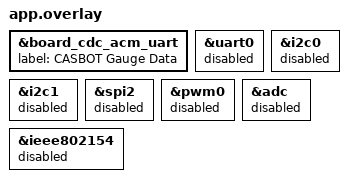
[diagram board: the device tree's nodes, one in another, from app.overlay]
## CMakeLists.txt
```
cmake_minimum_required(VERSION 3.20.0)

find_package(Zephyr REQUIRED HINTS $ENV{ZEPHYR_BASE})
project(trical_bridge LANGUAGES C)

add_subdirectory(lib)
target_sources(app PRIVATE src/main.c)
```

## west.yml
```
manifest:
  version: "1.2"
  self:
    path: trical_bridge
  projects:
    - name: zephyr
      url: https://github.com/zephyrproject-rtos/zephyr
      revision: v4.5.0
      import:
        name-allowlist:
          - cmsis
          - cmsis_6
          - hal_nordic
          - segger
```

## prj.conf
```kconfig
# BLE central/client foundation for three independent indicators. Explicit connections only.
CONFIG_BT=y
CONFIG_BT_CENTRAL=y
CONFIG_BT_GATT_CLIENT=y
CONFIG_BT_MAX_CONN=3
CONFIG_BT_DEVICE_NAME="CASBOT Gauge Bridge"

# Dedicated USB data port; never route the console or logging into it.
CONFIG_USB_DEVICE_STACK_NEXT=y
CONFIG_CDC_ACM_SERIAL_INITIALIZE_AT_BOOT=y
CONFIG_CDC_ACM_SERIAL_PRODUCT_STRING="CASBOT Gauge Bridge (development)"
CONFIG_SERIAL=y
CONFIG_UART_INTERRUPT_DRIVEN=y
CONFIG_UART_LINE_CTRL=y
CONFIG_CONSOLE=n
CONFIG_UART_CONSOLE=n
CONFIG_BOOT_BANNER=n
CONFIG_PRINTK=n

# Diagnostics use a non-blocking RTT backend, independent of USB consumption.
CONFIG_LOG=y
CONFIG_USE_SEGGER_RTT=y
CONFIG_LOG_BACKEND_RTT=y
CONFIG_LOG_BACKEND_UART=n
CONFIG_LOG_BACKEND_RTT_MODE_DROP=y
CONFIG_LOG_PROCESS_THREAD_STARTUP_DELAY_MS=0

CONFIG_MAIN_STACK_SIZE=4096
```

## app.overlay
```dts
/* Reuse the upstream board's CDC ACM instance; do not add a second port. */
&board_cdc_acm_uart {
	label = "CASBOT Gauge Data";
};

/* This USB/BLE bridge does not use the board's external peripheral pins. */
&uart0 {
	status = "disabled";
};

&i2c0 {
	status = "disabled";
};

&i2c1 {
	status = "disabled";
};

&spi2 {
	status = "disabled";
};

&pwm0 {
	status = "disabled";
};

&adc {
	status = "disabled";
};

&ieee802154 {
	status = "disabled";
};
```

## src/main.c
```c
#include "bridge_app.h"

int main(void)
{
	return bridge_run(false);
}
```
